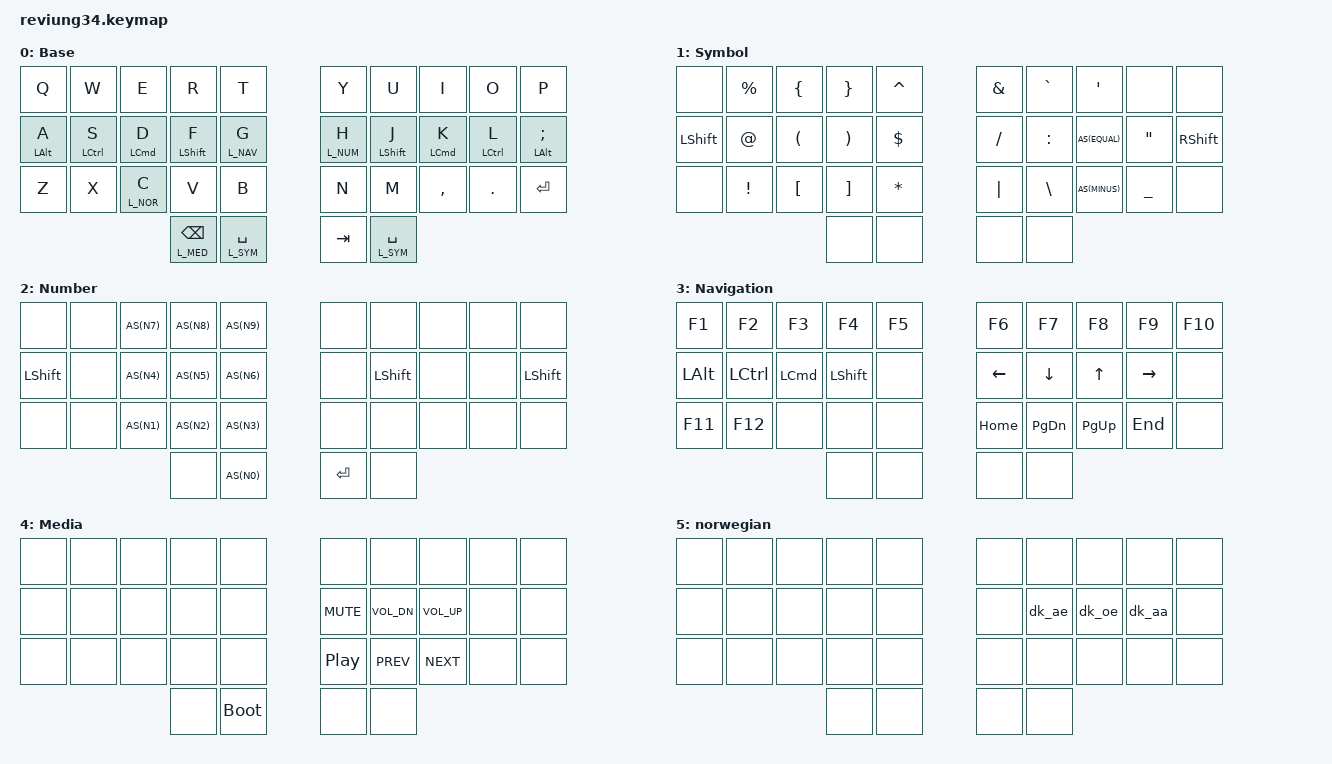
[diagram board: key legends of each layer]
/*
 * Copyright (c) 2023 The ZMK Contributors
 *
 * SPDX-License-Identifier: MIT
 */

#include <behaviors.dtsi>
#include <dt-bindings/zmk/bt.h>
#include <dt-bindings/zmk/keys.h>
#include <dt-bindings/zmk/rgb.h>

#define HOST_OS 2
#include "../zmk-nodefree-config/helper.h"
#include "../zmk-nodefree-config/keypos_def/keypos_34keys.h"
#include "../zmk-nodefree-config/international_chars/danish.dtsi"

#define L_DEF 0
#define L_SYM 1
#define L_NUM 2
#define L_NAV 3
#define L_MED 4
#define L_NOR 5

#define AS(keycode) &as LS(keycode) keycode 

/ {
    chosen {
        // 34 keys.
        zmk,matrix_transform = &dual_1u_transform;

        // 33 keys. Center two thumb keys replaced by a single 2u key. Remember to adjust your
        // keymap accordingly!
        // zmk,matrix_transform = &single_2u_transform;
    };
};

/ {
  combos {
    compatible = "zmk,combos";

    combo_esc {
      timeout-ms = <50>;
      key-positions = <RM1 RM2>;
      bindings = <&kp ESC>;
    };

    combo_enter {
      timeout-ms = <50>;
      key-positions = <LM1 LM2>;
      bindings = <&kp ENTER>;
    };

    combo_caps_word {
      timeout-ms = <50>;
      key-positions = <LB1 LB2>;
      bindings = <&caps_word>;
    };
  };
};

/ {
  behaviors {
    as: auto_shift {
      compatible = "zmk,behavior-hold-tap";
      #binding-cells = <2>;
      tapping-term-ms = <150>;
      quick-tap-ms = <0>;
      flavor = "tap-preferred";
      bindings = <&kp>, <&kp>;
    };

		hm: homerow_mods {
			compatible = "zmk,behavior-hold-tap";
			#binding-cells = <2>;
			tapping-term-ms = <150>;
			quick-tap-ms = <0>;
			flavor = "tap-preferred";
			bindings = <&kp>, <&kp>;
		};
  };

    keymap {
        compatible = "zmk,keymap";

        base {
            display-name = "Base";
            bindings = <
&kp Q       &kp W       &kp E      				&kp R          		&kp T       &kp Y      			&kp U         &kp I          &kp O         &kp P
&hm LALT A  &hm LCTRL S &hm LCMD D 				&hm LSHIFT F   		&lt L_NAV G	&lt L_NUM H			&hm LSHIFT J  &hm LCMD K     &hm LCTRL L   &hm LALT SEMI
&kp Z       &kp X       &lt L_NOR C				&kp V          		&kp B       &kp N      			&kp M         &kp COMMA      &kp DOT       &kp ENTER
                        &lt L_MED BSPC  	&lt L_SYM SPACE		&kp TAB     &lt L_SYM SPACE 
            >;
        };

        symbol {
          display-name = "Symbol";
          bindings = <
&none				&kp PRCNT		&kp LBRC    &kp RBRC      &kp CARET   &kp AMPS    &kp GRAVE    &kp APOS       &none         &none
&kp LSHIFT  &kp AT      &kp LPAR    &kp RPAR      &kp DOLLAR  &kp SLASH   &kp COLON    AS(EQUAL)      &kp DQT       &kp RSHIFT
&none       &kp EXCL    &kp LBKT    &kp RBKT      &kp STAR    &kp PIPE    &kp BSLH     AS(MINUS)      &kp UNDER     &none
                        &none       &none         &none       &none
          >;
        };

        number {
          display-name = "Number";
          bindings = <
&none       &none       AS(N7)     	AS(N8)      AS(N9)      &none       &none					&none					&none					&none
&kp LSHIFT	&none				AS(N4)			AS(N5)			AS(N6)			&none				&kp LSHIFT		&none					&none					&kp LSHIFT
&none				&none			  AS(N1)			AS(N2)			AS(N3)			&none				&none					&none					&none					&none
												&none				AS(N0)			&kp ENTER		&none
          >;
        };

				navig {
					display-name = "Navigation";
					bindings = <
&kp F1			&kp F2			&kp F3			&kp F4				&kp F5			&kp F6			&kp F7				&kp F8				&kp F9				&kp F10
&kp LALT		&kp LCTRL		&kp LCMD		&kp LSHIFT		&none				&kp LEFT		&kp DOWN			&kp UP				&kp RIGHT			&none
&kp F11			&kp F12			&none				&none					&none				&kp HOME		&kp PG_DN			&kp PG_UP			&kp END				&none
												&none				&none					&none				&none
					>;
				};

				media {
					display-name = "Media";
					bindings = <
&none				&none				&none				&none					&none				&none				&none					&none					&none					&none
&none				&none				&none				&none					&none				&kp K_MUTE	&kp C_VOL_DN	&kp C_VOL_UP	&none					&none
&none				&none				&none				&none					&none				&kp C_PP		&kp C_PREV		&kp C_NEXT		&none					&none
												&none				&bootloader		&none				&none
					>;
				};

				norwegian {
					display-name = "norwegian";
					bindings = <
&none				&none				&none				&none					&none				&none				&none					&none					&none					&none
&none				&none				&none				&none					&none				&none				&dk_ae			&dk_oe				&dk_aa				&none
&none				&none				&none				&none					&none				&none 			&none 				&none  				&none					&none
												&none				&none					&none				&none
					>;
				};
    };
};
